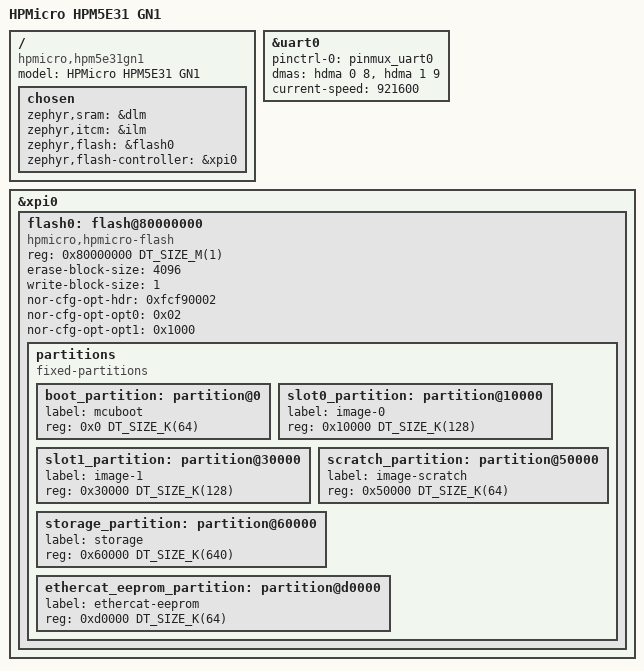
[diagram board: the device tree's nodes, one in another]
/dts-v1/;
#include <hpmicro/hpm5e31.dtsi>
#include "hpm5e31gn1-pinctrl.dtsi"
/ {
 model = "HPMicro HPM5E31 GN1";
 compatible = "hpmicro,hpm5e31gn1";
 chosen {
  zephyr,sram = &dlm;
  zephyr,itcm = &ilm;
  zephyr,flash = &flash0;
  zephyr,flash-controller = &xpi0;
 };
};
&uart0 {
 pinctrl-0 = <&pinmux_uart0>;
 pinctrl-names = "default";
 dmas = <&hdma 0 8>, <&hdma 1 9>;
 dma-names = "rx", "tx";
 current-speed = <921600>;
};
&xpi0 {
 status = "okay";
 flash0: flash@80000000 {
  compatible = "hpmicro,hpmicro-flash", "soc-nv-flash";
  reg = <0x80000000 DT_SIZE_M(1)>;
  erase-block-size = <4096>;
  write-block-size = <1>;
  nor-cfg-opt-hdr = <0xfcf90002>;
  nor-cfg-opt-opt0 = <0x02>;
  nor-cfg-opt-opt1 = <0x1000>;
  status = "okay";
		partitions {
			compatible = "fixed-partitions";
			#address-cells = <1>;
			#size-cells = <1>;

			boot_partition: partition@0 {
				label = "mcuboot";
				reg = <0x0 DT_SIZE_K(64)>;
			};

			slot0_partition: partition@10000 {
				label = "image-0";
				reg = <0x10000 DT_SIZE_K(128)>;
			};

			slot1_partition: partition@30000 {
				label = "image-1";
				reg = <0x30000 DT_SIZE_K(128)>;
			};

			scratch_partition: partition@50000 {
				label = "image-scratch";
				reg = <0x50000 DT_SIZE_K(64)>;
			};

			storage_partition: partition@60000 {
				label = "storage";
				reg = <0x60000 DT_SIZE_K(640)>;
			};

			ethercat_eeprom_partition: partition@d0000 {
				label = "ethercat-eeprom";
				reg = <0xd0000 DT_SIZE_K(64)>;
			};
		};

 };
};
